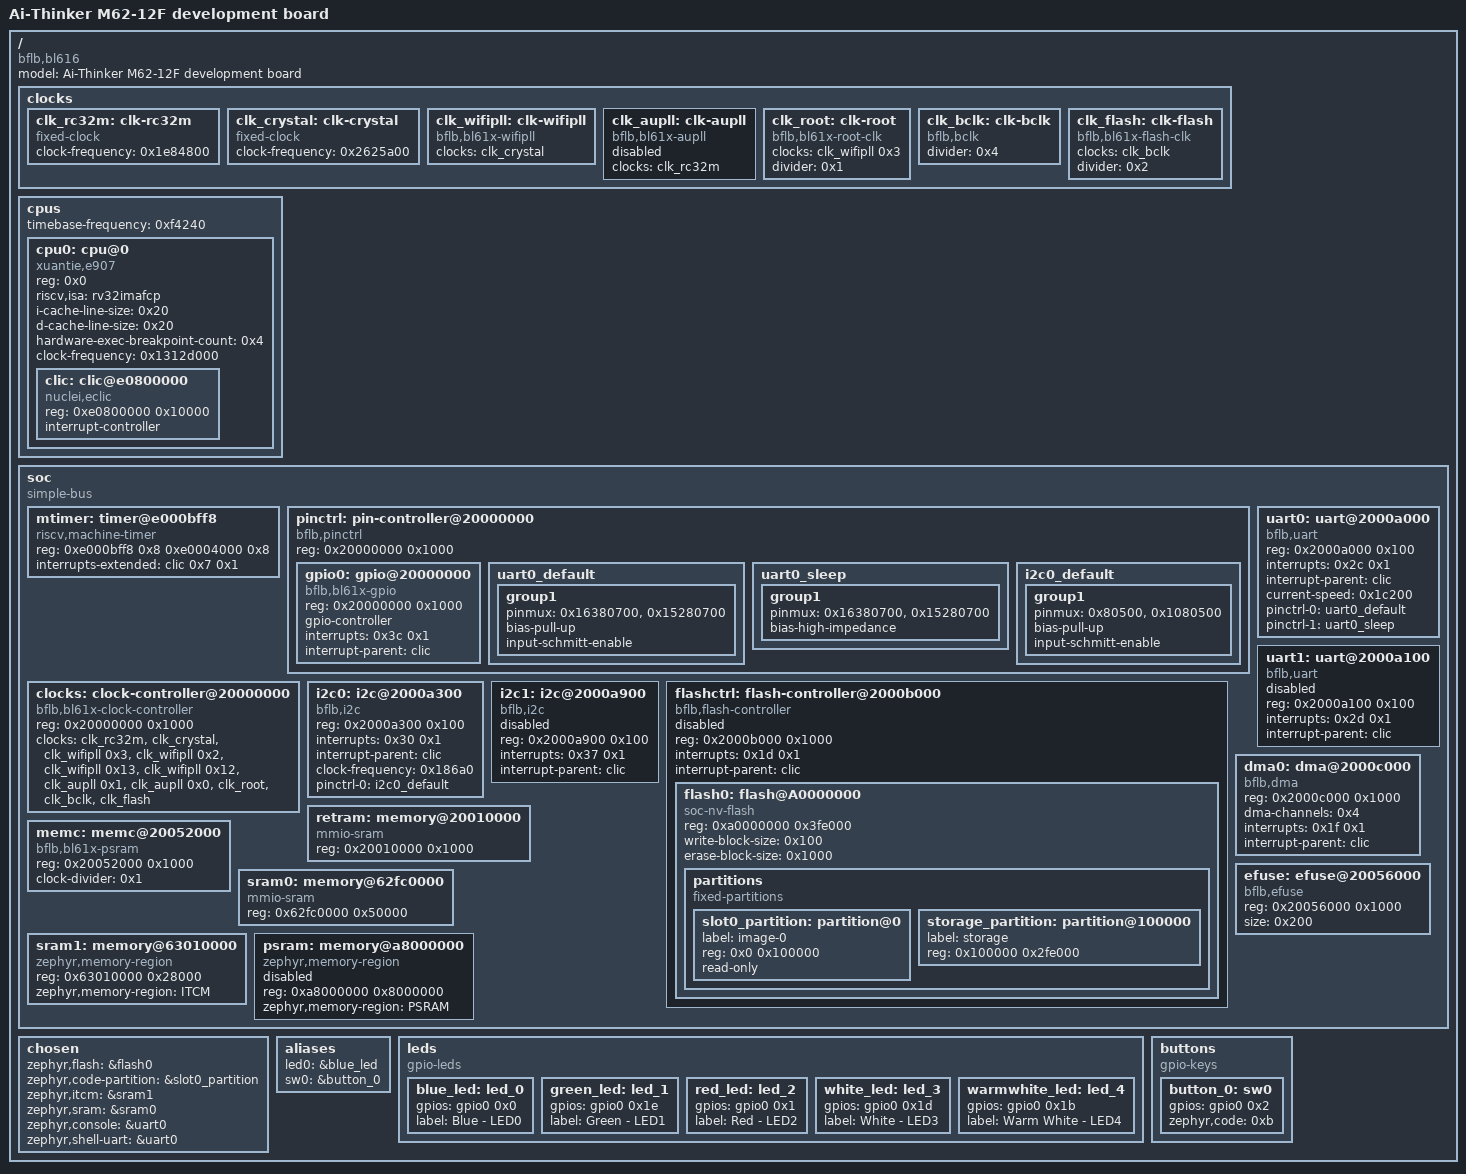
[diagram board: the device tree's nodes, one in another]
/dts-v1/;

/* node '/' defined in zephyr/dts/riscv/bflb/bl61x.dtsi:16 */
/ {
	#address-cells = < 0x1 >;                       /* in zephyr/dts/riscv/bflb/bl61x.dtsi:17 */
	#size-cells = < 0x1 >;                          /* in zephyr/dts/riscv/bflb/bl61x.dtsi:18 */
	model = "Ai-Thinker M62-12F development board"; /* in zephyr/boards/aithinker/ai_m62_12f/ai_m62_12f.dts:13 */
	compatible = "bflb,bl616";                      /* in zephyr/boards/aithinker/ai_m62_12f/ai_m62_12f.dts:14 */

	/* node '/clocks' defined in zephyr/dts/riscv/bflb/bl61x.dtsi:20 */
	clocks {

		/* node '/clocks/clk-rc32m' defined in zephyr/dts/riscv/bflb/bl61x.dtsi:21 */
		clk_rc32m: clk-rc32m {
			#clock-cells = < 0x0 >;          /* in zephyr/dts/riscv/bflb/bl61x.dtsi:22 */
			compatible = "fixed-clock";      /* in zephyr/dts/riscv/bflb/bl61x.dtsi:23 */
			clock-frequency = < 0x1e84800 >; /* in zephyr/dts/riscv/bflb/bl61x.dtsi:24 */
			status = "okay";                 /* in zephyr/dts/riscv/bflb/bl61x.dtsi:25 */
			phandle = < 0x2 >;               /* in zephyr/dts/riscv/bflb/bl61x.dtsi:45 */
		};

		/* node '/clocks/clk-crystal' defined in zephyr/dts/riscv/bflb/bl61x.dtsi:28 */
		clk_crystal: clk-crystal {
			#clock-cells = < 0x0 >;          /* in zephyr/dts/riscv/bflb/bl61x.dtsi:29 */
			compatible = "fixed-clock";      /* in zephyr/dts/riscv/bflb/bl61x.dtsi:30 */
			clock-frequency = < 0x2625a00 >; /* in zephyr/dts/riscv/bflb/bl61x.dtsi:31 */
			status = "okay";                 /* in zephyr/dts/riscv/bflb/bl61x.dtsi:32 */
			phandle = < 0x1 >;               /* in zephyr/dts/riscv/bflb/bl61x.dtsi:38 */
		};

		/* node '/clocks/clk-wifipll' defined in zephyr/dts/riscv/bflb/bl61x.dtsi:35 */
		clk_wifipll: clk-wifipll {
			#clock-cells = < 0x1 >;            /* in zephyr/dts/riscv/bflb/bl61x.dtsi:36 */
			compatible = "bflb,bl61x-wifipll"; /* in zephyr/dts/riscv/bflb/bl61x.dtsi:37 */
			clocks = < &clk_crystal >;         /* in zephyr/dts/riscv/bflb/bl61x.dtsi:38 */
			status = "okay";                   /* in zephyr/dts/riscv/bflb/bl61x.dtsi:39 */
			phandle = < 0x3 >;                 /* in zephyr/dts/riscv/bflb/bl61x.dtsi:52 */
		};

		/* node '/clocks/clk-aupll' defined in zephyr/dts/riscv/bflb/bl61x.dtsi:42 */
		clk_aupll: clk-aupll {
			#clock-cells = < 0x1 >;          /* in zephyr/dts/riscv/bflb/bl61x.dtsi:43 */
			compatible = "bflb,bl61x-aupll"; /* in zephyr/dts/riscv/bflb/bl61x.dtsi:44 */
			clocks = < &clk_rc32m >;         /* in zephyr/dts/riscv/bflb/bl61x.dtsi:45 */
			status = "disabled";             /* in zephyr/dts/riscv/bflb/bl61x.dtsi:46 */
			phandle = < 0x6 >;               /* in zephyr/dts/riscv/bflb/bl61x.dtsi:141 */
		};

		/* node '/clocks/clk-root' defined in zephyr/dts/riscv/bflb/bl61x.dtsi:49 */
		clk_root: clk-root {
			#clock-cells = < 0x0 >;             /* in zephyr/dts/riscv/bflb/bl61x.dtsi:50 */
			compatible = "bflb,bl61x-root-clk"; /* in zephyr/dts/riscv/bflb/bl61x.dtsi:51 */
			clocks = < &clk_wifipll 0x3 >;      /* in zephyr/dts/riscv/bflb/bl61x.dtsi:52 */
			divider = < 0x1 >;                  /* in zephyr/dts/riscv/bflb/bl61x.dtsi:53 */
			status = "okay";                    /* in zephyr/dts/riscv/bflb/bl61x.dtsi:54 */
			phandle = < 0x7 >;                  /* in zephyr/dts/riscv/bflb/bl61x.dtsi:141 */
		};

		/* node '/clocks/clk-bclk' defined in zephyr/dts/riscv/bflb/bl61x.dtsi:57 */
		clk_bclk: clk-bclk {
			#clock-cells = < 0x0 >;   /* in zephyr/dts/riscv/bflb/bl61x.dtsi:58 */
			compatible = "bflb,bclk"; /* in zephyr/dts/riscv/bflb/bl61x.dtsi:59 */
			divider = < 0x4 >;        /* in zephyr/dts/riscv/bflb/bl61x.dtsi:60 */
			status = "okay";          /* in zephyr/dts/riscv/bflb/bl61x.dtsi:61 */
			phandle = < 0x4 >;        /* in zephyr/dts/riscv/bflb/bl61x.dtsi:67 */
		};

		/* node '/clocks/clk-flash' defined in zephyr/dts/riscv/bflb/bl61x.dtsi:64 */
		clk_flash: clk-flash {
			#clock-cells = < 0x0 >;              /* in zephyr/dts/riscv/bflb/bl61x.dtsi:65 */
			compatible = "bflb,bl61x-flash-clk"; /* in zephyr/dts/riscv/bflb/bl61x.dtsi:66 */
			clocks = < &clk_bclk >;              /* in zephyr/dts/riscv/bflb/bl61x.dtsi:67 */
			divider = < 0x2 >;                   /* in zephyr/dts/riscv/bflb/bl61x.dtsi:68 */
			status = "okay";                     /* in zephyr/dts/riscv/bflb/bl61x.dtsi:69 */
			phandle = < 0x8 >;                   /* in zephyr/dts/riscv/bflb/bl61x.dtsi:141 */
		};
	};

	/* node '/cpus' defined in zephyr/dts/riscv/bflb/bl61x.dtsi:73 */
	cpus {
		#address-cells = < 0x1 >;         /* in zephyr/dts/riscv/bflb/bl61x.dtsi:74 */
		#size-cells = < 0x0 >;            /* in zephyr/dts/riscv/bflb/bl61x.dtsi:75 */
		timebase-frequency = < 0xf4240 >; /* in zephyr/dts/riscv/bflb/bl61x.dtsi:76 */

		/* node '/cpus/cpu@0' defined in zephyr/dts/riscv/bflb/bl61x.dtsi:78 */
		cpu0: cpu@0 {
			device_type = "cpu";                      /* in zephyr/dts/riscv/bflb/bl61x.dtsi:79 */
			compatible = "xuantie,e907",
			             "riscv";                     /* in zephyr/dts/riscv/bflb/bl61x.dtsi:80 */
			reg = < 0x0 >;                            /* in zephyr/dts/riscv/bflb/bl61x.dtsi:81 */
			riscv,isa = "rv32imafcp";                 /* in zephyr/dts/riscv/bflb/bl61x.dtsi:82 */
			i-cache-line-size = < 0x20 >;             /* in zephyr/dts/riscv/bflb/bl61x.dtsi:83 */
			d-cache-line-size = < 0x20 >;             /* in zephyr/dts/riscv/bflb/bl61x.dtsi:84 */
			hardware-exec-breakpoint-count = < 0x4 >; /* in zephyr/dts/riscv/bflb/bl61x.dtsi:85 */
			status = "okay";                          /* in zephyr/dts/riscv/bflb/bl61x.dtsi:86 */
			#address-cells = < 0x1 >;                 /* in zephyr/dts/riscv/bflb/bl61x.dtsi:88 */
			#size-cells = < 0x1 >;                    /* in zephyr/dts/riscv/bflb/bl61x.dtsi:89 */
			clock-frequency = < 0x1312d000 >;         /* in zephyr/boards/aithinker/ai_m62_12f/ai_m62_12f.dts:70 */

			/* node '/cpus/cpu@0/clic@e0800000' defined in zephyr/dts/riscv/bflb/bl61x.dtsi:91 */
			clic: clic@e0800000 {
				compatible = "nuclei,eclic";  /* in zephyr/dts/riscv/bflb/bl61x.dtsi:92 */
				reg = < 0xe0800000 0x10000 >; /* in zephyr/dts/riscv/bflb/bl61x.dtsi:93 */
				#address-cells = < 0x0 >;     /* in zephyr/dts/riscv/bflb/bl61x.dtsi:94 */
				#interrupt-cells = < 0x2 >;   /* in zephyr/dts/riscv/bflb/bl61x.dtsi:95 */
				interrupt-controller;         /* in zephyr/dts/riscv/bflb/bl61x.dtsi:96 */
				phandle = < 0x5 >;            /* in zephyr/dts/riscv/bflb/bl61x.dtsi:112 */
			};
		};
	};

	/* node '/soc' defined in zephyr/dts/riscv/bflb/bl61x.dtsi:101 */
	soc {
		compatible = "simple-bus"; /* in zephyr/dts/riscv/bflb/bl61x.dtsi:102 */
		#address-cells = < 0x1 >;  /* in zephyr/dts/riscv/bflb/bl61x.dtsi:103 */
		#size-cells = < 0x1 >;     /* in zephyr/dts/riscv/bflb/bl61x.dtsi:104 */
		ranges;                    /* in zephyr/dts/riscv/bflb/bl61x.dtsi:105 */

		/* node '/soc/timer@e000bff8' defined in zephyr/dts/riscv/bflb/bl61x.dtsi:107 */
		mtimer: timer@e000bff8 {
			compatible = "riscv,machine-timer";      /* in zephyr/dts/riscv/bflb/bl61x.dtsi:108 */
			reg = < 0xe000bff8 0x8 0xe0004000 0x8 >; /* in zephyr/dts/riscv/bflb/bl61x.dtsi:109 */
			reg-names = "mtime",
			            "mtimecmp";                  /* in zephyr/dts/riscv/bflb/bl61x.dtsi:110 */
			interrupts-extended = < &clic 0x7 0x1 >; /* in zephyr/dts/riscv/bflb/bl61x.dtsi:112 */
		};

		/* node '/soc/pin-controller@20000000' defined in zephyr/dts/riscv/bflb/bl61x.dtsi:115 */
		pinctrl: pin-controller@20000000 {
			compatible = "bflb,pinctrl";               /* in zephyr/dts/riscv/bflb/bl61x.dtsi:116 */
			reg = < 0x20000000 0x1000 >;               /* in zephyr/dts/riscv/bflb/bl61x.dtsi:117 */
			ranges = < 0x20000000 0x20000000 0x1000 >; /* in zephyr/dts/riscv/bflb/bl61x.dtsi:118 */
			#address-cells = < 0x1 >;                  /* in zephyr/dts/riscv/bflb/bl61x.dtsi:119 */
			#size-cells = < 0x1 >;                     /* in zephyr/dts/riscv/bflb/bl61x.dtsi:120 */
			status = "okay";                           /* in zephyr/dts/riscv/bflb/bl61x.dtsi:121 */

			/* node '/soc/pin-controller@20000000/gpio@20000000' defined in zephyr/dts/riscv/bflb/bl61x.dtsi:123 */
			gpio0: gpio@20000000 {
				compatible = "bflb,bl61x-gpio"; /* in zephyr/dts/riscv/bflb/bl61x.dtsi:124 */
				reg = < 0x20000000 0x1000 >;    /* in zephyr/dts/riscv/bflb/bl61x.dtsi:125 */
				#gpio-cells = < 0x2 >;          /* in zephyr/dts/riscv/bflb/bl61x.dtsi:126 */
				#bflb,pin-cells = < 0x2 >;      /* in zephyr/dts/riscv/bflb/bl61x.dtsi:127 */
				gpio-controller;                /* in zephyr/dts/riscv/bflb/bl61x.dtsi:130 */
				interrupts = < 0x3c 0x1 >;      /* in zephyr/dts/riscv/bflb/bl61x.dtsi:131 */
				interrupt-parent = < &clic >;   /* in zephyr/dts/riscv/bflb/bl61x.dtsi:132 */
				status = "okay";                /* in zephyr/boards/aithinker/ai_m62_12f/ai_m62_12f.dts:109 */
				phandle = < 0xc >;              /* in zephyr/boards/aithinker/ai_m62_12f/ai_m62_12f.dts:34 */
			};

			/* node '/soc/pin-controller@20000000/uart0_default' defined in zephyr/boards/aithinker/ai_m62_12f/ai_m62_12f-pinctrl.dtsi:10 */
			uart0_default: uart0_default {
				phandle = < 0x9 >; /* in zephyr/boards/aithinker/ai_m62_12f/ai_m62_12f.dts:103 */

				/* node '/soc/pin-controller@20000000/uart0_default/group1' defined in zephyr/boards/aithinker/ai_m62_12f/ai_m62_12f-pinctrl.dtsi:11 */
				group1 {
					pinmux = < 0x16380700 >,
					         < 0x15280700 >; /* in zephyr/boards/aithinker/ai_m62_12f/ai_m62_12f-pinctrl.dtsi:12 */
					bias-pull-up;            /* in zephyr/boards/aithinker/ai_m62_12f/ai_m62_12f-pinctrl.dtsi:14 */
					input-schmitt-enable;    /* in zephyr/boards/aithinker/ai_m62_12f/ai_m62_12f-pinctrl.dtsi:15 */
				};
			};

			/* node '/soc/pin-controller@20000000/uart0_sleep' defined in zephyr/boards/aithinker/ai_m62_12f/ai_m62_12f-pinctrl.dtsi:19 */
			uart0_sleep: uart0_sleep {
				phandle = < 0xa >; /* in zephyr/boards/aithinker/ai_m62_12f/ai_m62_12f.dts:104 */

				/* node '/soc/pin-controller@20000000/uart0_sleep/group1' defined in zephyr/boards/aithinker/ai_m62_12f/ai_m62_12f-pinctrl.dtsi:20 */
				group1 {
					pinmux = < 0x16380700 >,
					         < 0x15280700 >; /* in zephyr/boards/aithinker/ai_m62_12f/ai_m62_12f-pinctrl.dtsi:21 */
					bias-high-impedance;     /* in zephyr/boards/aithinker/ai_m62_12f/ai_m62_12f-pinctrl.dtsi:23 */
				};
			};

			/* node '/soc/pin-controller@20000000/i2c0_default' defined in zephyr/boards/aithinker/ai_m62_12f/ai_m62_12f-pinctrl.dtsi:27 */
			i2c0_default: i2c0_default {
				phandle = < 0xb >; /* in zephyr/boards/aithinker/ai_m62_12f/ai_m62_12f.dts:116 */

				/* node '/soc/pin-controller@20000000/i2c0_default/group1' defined in zephyr/boards/aithinker/ai_m62_12f/ai_m62_12f-pinctrl.dtsi:28 */
				group1 {
					pinmux = < 0x80500 >,
					         < 0x1080500 >; /* in zephyr/boards/aithinker/ai_m62_12f/ai_m62_12f-pinctrl.dtsi:29 */
					bias-pull-up;           /* in zephyr/boards/aithinker/ai_m62_12f/ai_m62_12f-pinctrl.dtsi:31 */
					input-schmitt-enable;   /* in zephyr/boards/aithinker/ai_m62_12f/ai_m62_12f-pinctrl.dtsi:32 */
				};
			};
		};

		/* node '/soc/clock-controller@20000000' defined in zephyr/dts/riscv/bflb/bl61x.dtsi:136 */
		clocks: clock-controller@20000000 {
			compatible = "bflb,bl61x-clock-controller",
			             "bflb,clock-controller";       /* in zephyr/dts/riscv/bflb/bl61x.dtsi:137 */
			reg = < 0x20000000 0x1000 >;                /* in zephyr/dts/riscv/bflb/bl61x.dtsi:138 */
			#clock-cells = < 0x1 >;                     /* in zephyr/dts/riscv/bflb/bl61x.dtsi:139 */
			status = "okay";                            /* in zephyr/dts/riscv/bflb/bl61x.dtsi:140 */
			clocks = < &clk_rc32m >,
			         < &clk_crystal >,
			         < &clk_wifipll 0x3 >,
			         < &clk_wifipll 0x2 >,
			         < &clk_wifipll 0x13 >,
			         < &clk_wifipll 0x12 >,
			         < &clk_aupll 0x1 >,
			         < &clk_aupll 0x0 >,
			         < &clk_root >,
			         < &clk_bclk >,
			         < &clk_flash >;                    /* in zephyr/dts/riscv/bflb/bl61x.dtsi:141 */
			clock-names = "rc32m",
			              "crystal",
			              "wifipll_320",
			              "wifipll_240",
			              "wifipll_480",
			              "wifipll_360",
			              "aupll_div1",
			              "aupll_div2",
			              "root",
			              "bclk",
			              "flash";                      /* in zephyr/dts/riscv/bflb/bl61x.dtsi:148 */
		};

		/* node '/soc/uart@2000a000' defined in zephyr/dts/riscv/bflb/bl61x.dtsi:157 */
		uart0: uart@2000a000 {
			compatible = "bflb,uart";       /* in zephyr/dts/riscv/bflb/bl61x.dtsi:158 */
			reg = < 0x2000a000 0x100 >;     /* in zephyr/dts/riscv/bflb/bl61x.dtsi:159 */
			interrupts = < 0x2c 0x1 >;      /* in zephyr/dts/riscv/bflb/bl61x.dtsi:160 */
			interrupt-parent = < &clic >;   /* in zephyr/dts/riscv/bflb/bl61x.dtsi:161 */
			status = "okay";                /* in zephyr/boards/aithinker/ai_m62_12f/ai_m62_12f.dts:100 */
			current-speed = < 0x1c200 >;    /* in zephyr/boards/aithinker/ai_m62_12f/ai_m62_12f.dts:101 */
			pinctrl-0 = < &uart0_default >; /* in zephyr/boards/aithinker/ai_m62_12f/ai_m62_12f.dts:103 */
			pinctrl-1 = < &uart0_sleep >;   /* in zephyr/boards/aithinker/ai_m62_12f/ai_m62_12f.dts:104 */
			pinctrl-names = "default",
			                "sleep";        /* in zephyr/boards/aithinker/ai_m62_12f/ai_m62_12f.dts:105 */
		};

		/* node '/soc/uart@2000a100' defined in zephyr/dts/riscv/bflb/bl61x.dtsi:165 */
		uart1: uart@2000a100 {
			compatible = "bflb,uart";     /* in zephyr/dts/riscv/bflb/bl61x.dtsi:166 */
			reg = < 0x2000a100 0x100 >;   /* in zephyr/dts/riscv/bflb/bl61x.dtsi:167 */
			interrupts = < 0x2d 0x1 >;    /* in zephyr/dts/riscv/bflb/bl61x.dtsi:168 */
			interrupt-parent = < &clic >; /* in zephyr/dts/riscv/bflb/bl61x.dtsi:169 */
			status = "disabled";          /* in zephyr/dts/riscv/bflb/bl61x.dtsi:170 */
		};

		/* node '/soc/i2c@2000a300' defined in zephyr/dts/riscv/bflb/bl61x.dtsi:173 */
		i2c0: i2c@2000a300 {
			compatible = "bflb,i2c";       /* in zephyr/dts/riscv/bflb/bl61x.dtsi:174 */
			reg = < 0x2000a300 0x100 >;    /* in zephyr/dts/riscv/bflb/bl61x.dtsi:175 */
			#address-cells = < 0x1 >;      /* in zephyr/dts/riscv/bflb/bl61x.dtsi:176 */
			#size-cells = < 0x0 >;         /* in zephyr/dts/riscv/bflb/bl61x.dtsi:177 */
			interrupts = < 0x30 0x1 >;     /* in zephyr/dts/riscv/bflb/bl61x.dtsi:180 */
			interrupt-parent = < &clic >;  /* in zephyr/dts/riscv/bflb/bl61x.dtsi:181 */
			status = "okay";               /* in zephyr/boards/aithinker/ai_m62_12f/ai_m62_12f.dts:113 */
			clock-frequency = < 0x186a0 >; /* in zephyr/boards/aithinker/ai_m62_12f/ai_m62_12f.dts:114 */
			pinctrl-0 = < &i2c0_default >; /* in zephyr/boards/aithinker/ai_m62_12f/ai_m62_12f.dts:116 */
			pinctrl-names = "default";     /* in zephyr/boards/aithinker/ai_m62_12f/ai_m62_12f.dts:117 */
		};

		/* node '/soc/i2c@2000a900' defined in zephyr/dts/riscv/bflb/bl61x.dtsi:184 */
		i2c1: i2c@2000a900 {
			compatible = "bflb,i2c";      /* in zephyr/dts/riscv/bflb/bl61x.dtsi:185 */
			reg = < 0x2000a900 0x100 >;   /* in zephyr/dts/riscv/bflb/bl61x.dtsi:186 */
			#address-cells = < 0x1 >;     /* in zephyr/dts/riscv/bflb/bl61x.dtsi:187 */
			#size-cells = < 0x0 >;        /* in zephyr/dts/riscv/bflb/bl61x.dtsi:188 */
			status = "disabled";          /* in zephyr/dts/riscv/bflb/bl61x.dtsi:189 */
			interrupts = < 0x37 0x1 >;    /* in zephyr/dts/riscv/bflb/bl61x.dtsi:191 */
			interrupt-parent = < &clic >; /* in zephyr/dts/riscv/bflb/bl61x.dtsi:192 */
		};

		/* node '/soc/flash-controller@2000b000' defined in zephyr/dts/riscv/bflb/bl61x.dtsi:195 */
		flashctrl: flash-controller@2000b000 {
			compatible = "bflb,flash-controller"; /* in zephyr/dts/riscv/bflb/bl61x.dtsi:196 */
			reg = < 0x2000b000 0x1000 >;          /* in zephyr/dts/riscv/bflb/bl61x.dtsi:197 */
			#address-cells = < 0x1 >;             /* in zephyr/dts/riscv/bflb/bl61x.dtsi:198 */
			#size-cells = < 0x1 >;                /* in zephyr/dts/riscv/bflb/bl61x.dtsi:199 */
			status = "disabled";                  /* in zephyr/dts/riscv/bflb/bl61x.dtsi:200 */
			interrupts = < 0x1d 0x1 >;            /* in zephyr/dts/riscv/bflb/bl61x.dtsi:202 */
			interrupt-parent = < &clic >;         /* in zephyr/dts/riscv/bflb/bl61x.dtsi:203 */

			/* node '/soc/flash-controller@2000b000/flash@A0000000' defined in zephyr/boards/aithinker/ai_m62_12f/ai_m62_12f.dts:74 */
			flash0: flash@A0000000 {
				compatible = "soc-nv-flash",
				             "gd,25lq32d";     /* in zephyr/boards/aithinker/ai_m62_12f/ai_m62_12f.dts:75 */
				reg = < 0xa0000000 0x3fe000 >; /* in zephyr/boards/aithinker/ai_m62_12f/ai_m62_12f.dts:76 */
				write-block-size = < 0x100 >;  /* in zephyr/boards/aithinker/ai_m62_12f/ai_m62_12f.dts:77 */
				erase-block-size = < 0x1000 >; /* in zephyr/boards/aithinker/ai_m62_12f/ai_m62_12f.dts:78 */

				/* node '/soc/flash-controller@2000b000/flash@A0000000/partitions' defined in zephyr/boards/aithinker/ai_m62_12f/ai_m62_12f.dts:80 */
				partitions {
					compatible = "fixed-partitions"; /* in zephyr/boards/aithinker/ai_m62_12f/ai_m62_12f.dts:81 */
					#address-cells = < 0x1 >;        /* in zephyr/boards/aithinker/ai_m62_12f/ai_m62_12f.dts:82 */
					#size-cells = < 0x1 >;           /* in zephyr/boards/aithinker/ai_m62_12f/ai_m62_12f.dts:83 */

					/* node '/soc/flash-controller@2000b000/flash@A0000000/partitions/partition@0' defined in zephyr/boards/aithinker/ai_m62_12f/ai_m62_12f.dts:85 */
					slot0_partition: partition@0 {
						label = "image-0";      /* in zephyr/boards/aithinker/ai_m62_12f/ai_m62_12f.dts:86 */
						reg = < 0x0 0x100000 >; /* in zephyr/boards/aithinker/ai_m62_12f/ai_m62_12f.dts:87 */
						read-only;              /* in zephyr/boards/aithinker/ai_m62_12f/ai_m62_12f.dts:88 */
					};

					/* node '/soc/flash-controller@2000b000/flash@A0000000/partitions/partition@100000' defined in zephyr/boards/aithinker/ai_m62_12f/ai_m62_12f.dts:91 */
					storage_partition: partition@100000 {
						label = "storage";           /* in zephyr/boards/aithinker/ai_m62_12f/ai_m62_12f.dts:92 */
						reg = < 0x100000 0x2fe000 >; /* in zephyr/boards/aithinker/ai_m62_12f/ai_m62_12f.dts:93 */
					};
				};
			};
		};

		/* node '/soc/dma@2000c000' defined in zephyr/dts/riscv/bflb/bl61x.dtsi:206 */
		dma0: dma@2000c000 {
			compatible = "bflb,dma";      /* in zephyr/dts/riscv/bflb/bl61x.dtsi:207 */
			reg = < 0x2000c000 0x1000 >;  /* in zephyr/dts/riscv/bflb/bl61x.dtsi:208 */
			#dma-cells = < 0x1 >;         /* in zephyr/dts/riscv/bflb/bl61x.dtsi:209 */
			dma-channels = < 0x4 >;       /* in zephyr/dts/riscv/bflb/bl61x.dtsi:210 */
			interrupts = < 0x1f 0x1 >;    /* in zephyr/dts/riscv/bflb/bl61x.dtsi:212 */
			interrupt-parent = < &clic >; /* in zephyr/dts/riscv/bflb/bl61x.dtsi:213 */
		};

		/* node '/soc/memory@20010000' defined in zephyr/dts/riscv/bflb/bl61x.dtsi:216 */
		retram: memory@20010000 {
			compatible = "mmio-sram";    /* in zephyr/dts/riscv/bflb/bl61x.dtsi:217 */
			reg = < 0x20010000 0x1000 >; /* in zephyr/dts/riscv/bflb/bl61x.dtsi:218 */
		};

		/* node '/soc/memc@20052000' defined in zephyr/dts/riscv/bflb/bl61x.dtsi:221 */
		memc: memc@20052000 {
			compatible = "bflb,bl61x-psram"; /* in zephyr/dts/riscv/bflb/bl61x.dtsi:222 */
			reg = < 0x20052000 0x1000 >;     /* in zephyr/dts/riscv/bflb/bl61x.dtsi:223 */
			clock-divider = < 0x1 >;         /* in zephyr/dts/riscv/bflb/bl61x.dtsi:224 */
			status = "okay";                 /* in zephyr/dts/riscv/bflb/bl61x.dtsi:225 */
		};

		/* node '/soc/efuse@20056000' defined in zephyr/dts/riscv/bflb/bl61x.dtsi:228 */
		efuse: efuse@20056000 {
			compatible = "bflb,efuse";   /* in zephyr/dts/riscv/bflb/bl61x.dtsi:229 */
			reg = < 0x20056000 0x1000 >; /* in zephyr/dts/riscv/bflb/bl61x.dtsi:230 */
			status = "okay";             /* in zephyr/dts/riscv/bflb/bl61x.dtsi:231 */
			size = < 0x200 >;            /* in zephyr/dts/riscv/bflb/bl61x.dtsi:232 */
		};

		/* node '/soc/memory@62fc0000' defined in zephyr/dts/riscv/bflb/bl61x.dtsi:235 */
		sram0: memory@62fc0000 {
			compatible = "mmio-sram";     /* in zephyr/dts/riscv/bflb/bl61x.dtsi:236 */
			reg = < 0x62fc0000 0x50000 >; /* in zephyr/dts/riscv/bflb/bl61x.dtsi:237 */
		};

		/* node '/soc/memory@63010000' defined in zephyr/dts/riscv/bflb/bl61x.dtsi:240 */
		sram1: memory@63010000 {
			compatible = "zephyr,memory-region",
			             "mmio-sram";            /* in zephyr/dts/riscv/bflb/bl61x.dtsi:241 */
			reg = < 0x63010000 0x28000 >;        /* in zephyr/dts/riscv/bflb/bl61x.dtsi:242 */
			zephyr,memory-region = "ITCM";       /* in zephyr/dts/riscv/bflb/bl61x.dtsi:243 */
		};

		/* node '/soc/memory@a8000000' defined in zephyr/dts/riscv/bflb/bl61x.dtsi:246 */
		psram: memory@a8000000 {
			compatible = "zephyr,memory-region"; /* in zephyr/dts/riscv/bflb/bl61x.dtsi:247 */
			reg = < 0xa8000000 0x8000000 >;      /* in zephyr/dts/riscv/bflb/bl61x.dtsi:248 */
			zephyr,memory-region = "PSRAM";      /* in zephyr/dts/riscv/bflb/bl61x.dtsi:249 */
			status = "disabled";                 /* in zephyr/dts/riscv/bflb/bl61x.dtsi:250 */
		};
	};

	/* node '/chosen' defined in zephyr/boards/aithinker/ai_m62_12f/ai_m62_12f.dts:16 */
	chosen {
		zephyr,flash = &flash0;                   /* in zephyr/boards/aithinker/ai_m62_12f/ai_m62_12f.dts:17 */
		zephyr,code-partition = &slot0_partition; /* in zephyr/boards/aithinker/ai_m62_12f/ai_m62_12f.dts:18 */
		zephyr,itcm = &sram1;                     /* in zephyr/boards/aithinker/ai_m62_12f/ai_m62_12f.dts:19 */
		zephyr,sram = &sram0;                     /* in zephyr/boards/aithinker/ai_m62_12f/ai_m62_12f.dts:20 */
		zephyr,console = &uart0;                  /* in zephyr/boards/aithinker/ai_m62_12f/ai_m62_12f.dts:21 */
		zephyr,shell-uart = &uart0;               /* in zephyr/boards/aithinker/ai_m62_12f/ai_m62_12f.dts:22 */
	};

	/* node '/aliases' defined in zephyr/boards/aithinker/ai_m62_12f/ai_m62_12f.dts:25 */
	aliases {
		led0 = &blue_led; /* in zephyr/boards/aithinker/ai_m62_12f/ai_m62_12f.dts:26 */
		sw0 = &button_0;  /* in zephyr/boards/aithinker/ai_m62_12f/ai_m62_12f.dts:27 */
	};

	/* node '/leds' defined in zephyr/boards/aithinker/ai_m62_12f/ai_m62_12f.dts:30 */
	leds {
		compatible = "gpio-leds"; /* in zephyr/boards/aithinker/ai_m62_12f/ai_m62_12f.dts:31 */

		/* node '/leds/led_0' defined in zephyr/boards/aithinker/ai_m62_12f/ai_m62_12f.dts:33 */
		blue_led: led_0 {
			gpios = < &gpio0 0x0 0x20 >; /* in zephyr/boards/aithinker/ai_m62_12f/ai_m62_12f.dts:34 */
			label = "Blue - LED0";       /* in zephyr/boards/aithinker/ai_m62_12f/ai_m62_12f.dts:35 */
		};

		/* node '/leds/led_1' defined in zephyr/boards/aithinker/ai_m62_12f/ai_m62_12f.dts:38 */
		green_led: led_1 {
			gpios = < &gpio0 0x1e 0x0 >; /* in zephyr/boards/aithinker/ai_m62_12f/ai_m62_12f.dts:39 */
			label = "Green - LED1";      /* in zephyr/boards/aithinker/ai_m62_12f/ai_m62_12f.dts:40 */
		};

		/* node '/leds/led_2' defined in zephyr/boards/aithinker/ai_m62_12f/ai_m62_12f.dts:43 */
		red_led: led_2 {
			gpios = < &gpio0 0x1 0x0 >; /* in zephyr/boards/aithinker/ai_m62_12f/ai_m62_12f.dts:44 */
			label = "Red - LED2";       /* in zephyr/boards/aithinker/ai_m62_12f/ai_m62_12f.dts:45 */
		};

		/* node '/leds/led_3' defined in zephyr/boards/aithinker/ai_m62_12f/ai_m62_12f.dts:48 */
		white_led: led_3 {
			gpios = < &gpio0 0x1d 0x0 >; /* in zephyr/boards/aithinker/ai_m62_12f/ai_m62_12f.dts:49 */
			label = "White - LED3";      /* in zephyr/boards/aithinker/ai_m62_12f/ai_m62_12f.dts:50 */
		};

		/* node '/leds/led_4' defined in zephyr/boards/aithinker/ai_m62_12f/ai_m62_12f.dts:53 */
		warmwhite_led: led_4 {
			gpios = < &gpio0 0x1b 0x0 >; /* in zephyr/boards/aithinker/ai_m62_12f/ai_m62_12f.dts:54 */
			label = "Warm White - LED4"; /* in zephyr/boards/aithinker/ai_m62_12f/ai_m62_12f.dts:55 */
		};
	};

	/* node '/buttons' defined in zephyr/boards/aithinker/ai_m62_12f/ai_m62_12f.dts:59 */
	buttons {
		compatible = "gpio-keys"; /* in zephyr/boards/aithinker/ai_m62_12f/ai_m62_12f.dts:60 */

		/* node '/buttons/sw0' defined in zephyr/boards/aithinker/ai_m62_12f/ai_m62_12f.dts:62 */
		button_0: sw0 {
			gpios = < &gpio0 0x2 0x0 >; /* in zephyr/boards/aithinker/ai_m62_12f/ai_m62_12f.dts:63 */
			zephyr,code = < 0xb >;      /* in zephyr/boards/aithinker/ai_m62_12f/ai_m62_12f.dts:64 */
		};
	};
};
